# headsail register map
Vendor: tuni.fi; File version: 1.0
CPU: other r1p0, little endian, no MPU, no FPU, vendor SysTick, 2 interrupt priority bits
Registers are 32-bit, read-write, no defined reset value unless marked. A register's access mark holds for its fields unless they carry their own. Offsets are from the block's base; [hi:lo] are bit positions; lines under a group give offsets from that group; {n}, {i} and the like mark numbered series; 'fields as' and 'values as' point back to an identical list.

## apb_pad_conf_reg_array
Base 0x1FFF07000
0x00 registers group
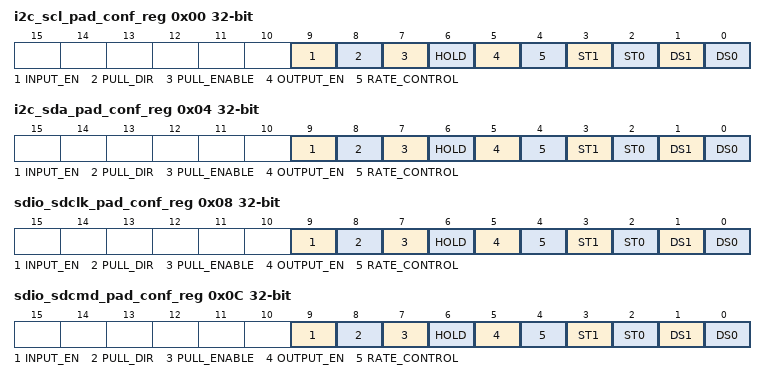
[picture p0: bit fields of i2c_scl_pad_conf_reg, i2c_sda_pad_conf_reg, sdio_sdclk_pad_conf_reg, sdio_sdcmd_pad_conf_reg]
  0x00 i2c_scl_pad_conf_reg
    [9] INPUT_EN, [8] PULL_DIR, [7] PULL_ENABLE, [6] HOLD, [5] OUTPUT_EN, [4] RATE_CONTROL, [3] ST1, [2] ST0, [1] DS1, [0] DS0
  0x04 i2c_sda_pad_conf_reg access not given
    fields as registers.i2c_scl_pad_conf_reg
  0x08 sdio_sdclk_pad_conf_reg access not given
    fields as registers.i2c_scl_pad_conf_reg
  0x0C sdio_sdcmd_pad_conf_reg access not given
    fields as registers.i2c_scl_pad_conf_reg
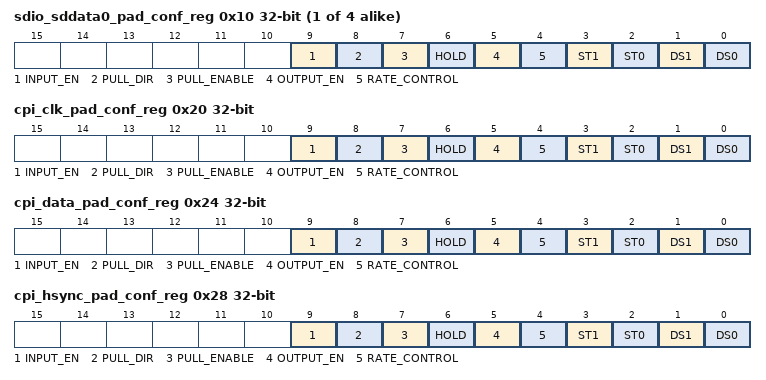
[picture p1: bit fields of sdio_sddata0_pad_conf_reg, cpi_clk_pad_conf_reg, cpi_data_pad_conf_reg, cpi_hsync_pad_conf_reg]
  {0x10+4j} sdio_sddata{j}_pad_conf_reg access not given (j=0..3)
    fields as registers.i2c_scl_pad_conf_reg
  0x20 cpi_clk_pad_conf_reg access not given
    fields as registers.i2c_scl_pad_conf_reg
  0x24 cpi_data_pad_conf_reg access not given
    fields as registers.i2c_scl_pad_conf_reg
  0x28 cpi_hsync_pad_conf_reg access not given
    fields as registers.i2c_scl_pad_conf_reg
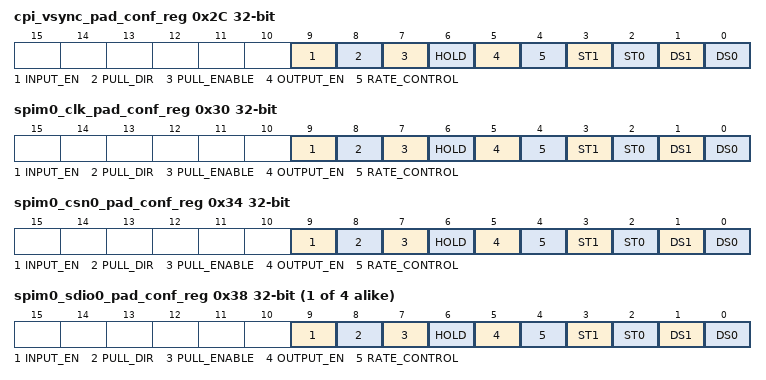
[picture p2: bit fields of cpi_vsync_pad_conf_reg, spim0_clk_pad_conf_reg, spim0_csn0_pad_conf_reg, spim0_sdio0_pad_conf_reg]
  0x2C cpi_vsync_pad_conf_reg access not given
    fields as registers.i2c_scl_pad_conf_reg
  0x30 spim0_clk_pad_conf_reg access not given
    fields as registers.i2c_scl_pad_conf_reg
  0x34 spim0_csn0_pad_conf_reg access not given
    fields as registers.i2c_scl_pad_conf_reg
  {0x38+4j} spim0_sdio{j}_pad_conf_reg access not given (j=0..3)
    fields as registers.i2c_scl_pad_conf_reg
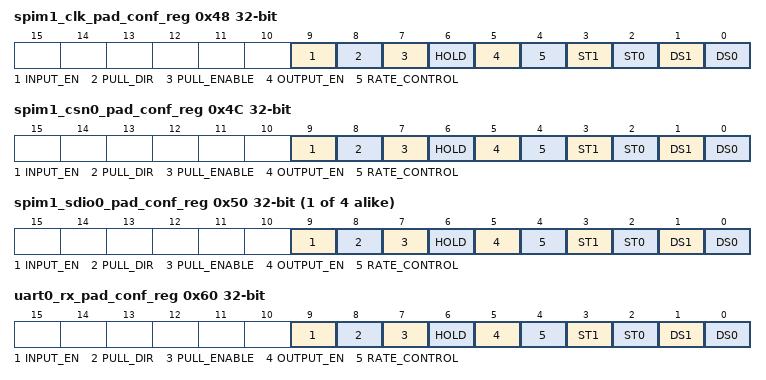
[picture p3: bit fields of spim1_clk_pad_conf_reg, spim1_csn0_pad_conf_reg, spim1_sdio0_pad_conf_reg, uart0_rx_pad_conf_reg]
  0x48 spim1_clk_pad_conf_reg access not given
    fields as registers.i2c_scl_pad_conf_reg
  0x4C spim1_csn0_pad_conf_reg access not given
    fields as registers.i2c_scl_pad_conf_reg
  {0x50+4j} spim1_sdio{j}_pad_conf_reg access not given (j=0..3)
    fields as registers.i2c_scl_pad_conf_reg
  0x60 uart0_rx_pad_conf_reg access not given
    fields as registers.i2c_scl_pad_conf_reg
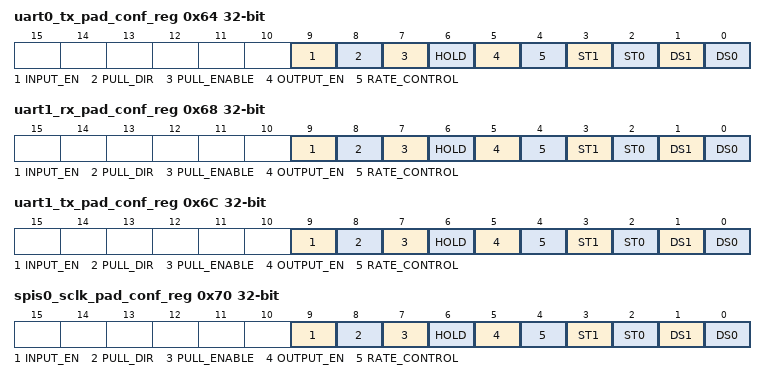
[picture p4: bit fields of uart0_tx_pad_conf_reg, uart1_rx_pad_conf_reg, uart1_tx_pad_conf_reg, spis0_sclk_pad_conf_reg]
  0x64 uart0_tx_pad_conf_reg access not given
    fields as registers.i2c_scl_pad_conf_reg
  0x68 uart1_rx_pad_conf_reg access not given
    fields as registers.i2c_scl_pad_conf_reg
  0x6C uart1_tx_pad_conf_reg access not given
    fields as registers.i2c_scl_pad_conf_reg
  0x70 spis0_sclk_pad_conf_reg access not given
    fields as registers.i2c_scl_pad_conf_reg
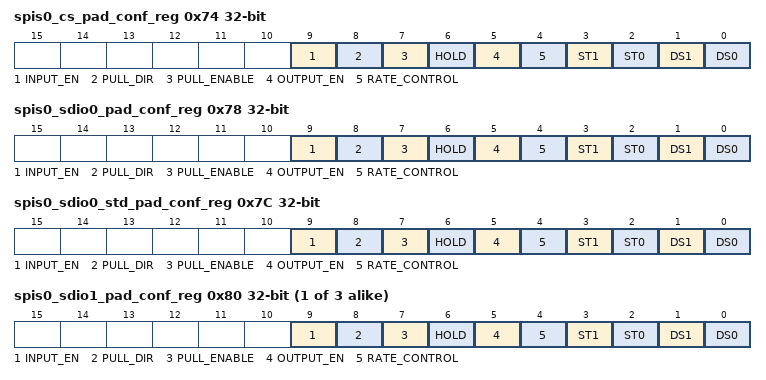
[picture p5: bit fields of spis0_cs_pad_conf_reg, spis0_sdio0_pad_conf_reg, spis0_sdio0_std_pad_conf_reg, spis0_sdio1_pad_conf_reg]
  0x74 spis0_cs_pad_conf_reg access not given
    fields as registers.i2c_scl_pad_conf_reg
  0x78 spis0_sdio0_pad_conf_reg access not given
    fields as registers.i2c_scl_pad_conf_reg
  0x7C spis0_sdio0_std_pad_conf_reg access not given
    fields as registers.i2c_scl_pad_conf_reg
  {0x7C+4j} spis0_sdio{j}_pad_conf_reg access not given (j=1..3)
    fields as registers.i2c_scl_pad_conf_reg
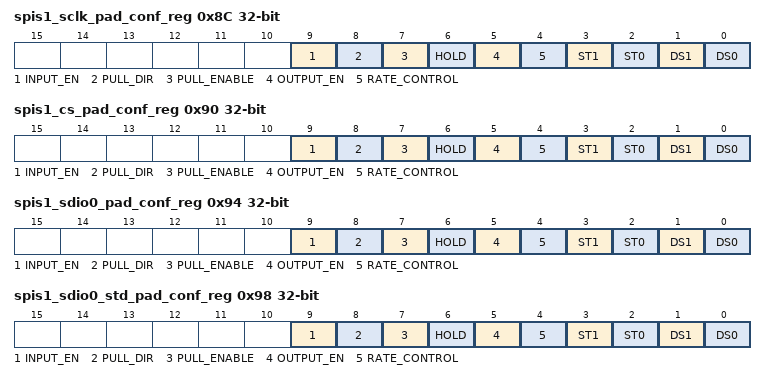
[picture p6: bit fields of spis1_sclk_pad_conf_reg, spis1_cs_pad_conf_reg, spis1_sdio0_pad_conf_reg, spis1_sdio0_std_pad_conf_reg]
  0x8C spis1_sclk_pad_conf_reg access not given
    fields as registers.i2c_scl_pad_conf_reg
  0x90 spis1_cs_pad_conf_reg access not given
    fields as registers.i2c_scl_pad_conf_reg
  0x94 spis1_sdio0_pad_conf_reg access not given
    fields as registers.i2c_scl_pad_conf_reg
  0x98 spis1_sdio0_std_pad_conf_reg access not given
    fields as registers.i2c_scl_pad_conf_reg
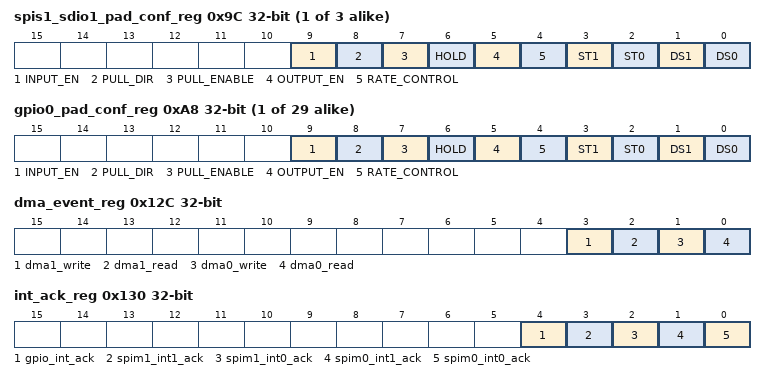
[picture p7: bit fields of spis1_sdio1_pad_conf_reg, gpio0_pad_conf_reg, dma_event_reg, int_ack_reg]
  {0x98+4j} spis1_sdio{j}_pad_conf_reg access not given (j=1..3)
    fields as registers.i2c_scl_pad_conf_reg
  {0xA8+4j} gpio{j}_pad_conf_reg access not given (j=0..28)
    fields as registers.i2c_scl_pad_conf_reg
  0x11C pad_mux0_reg access not given
    [1:0] mux_select_0
  {0x11C+4j} pad_mux{j}_reg access not given (j=1..3)
    [1:0] mux_select
  0x12C dma_event_reg access not given
    [3] dma1_write, [2] dma1_read, [1] dma0_write, [0] dma0_read
  0x130 int_ack_reg
    [4] gpio_int_ack — Acknowledge that the gpio irq is handled to de-assert the interrupt
    [3] spim1_int1_ack — Acknowledge that the spim1_events1 is handled to de-assert the interrupt
    [2] spim1_int0_ack — Acknowledge that the spim1_events0 is handled to de-assert the interrupt
    [1] spim0_int1_ack — Acknowledge that the spim0_events1 is handled to de-assert the interrupt
    [0] spim0_int0_ack — Acknowledge that the spim0_events0 is handled to de-assert the interrupt
